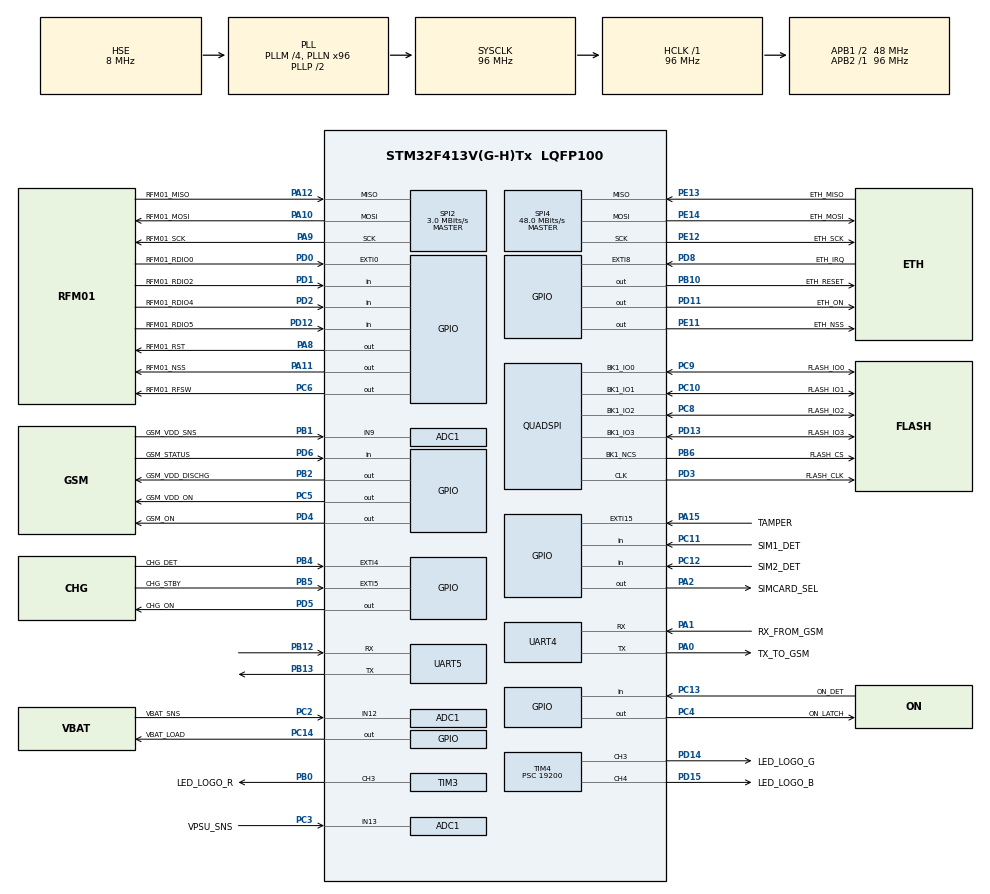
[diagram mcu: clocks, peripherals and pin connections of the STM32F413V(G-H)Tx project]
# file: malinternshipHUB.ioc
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ADC1.Channel-0\#ChannelRegularConversion=ADC_CHANNEL_12
ADC1.Channel-4\#ChannelRegularConversion=ADC_CHANNEL_13
ADC1.Channel-6\#ChannelRegularConversion=ADC_CHANNEL_9
ADC1.Channel-7\#ChannelRegularConversion=ADC_CHANNEL_VREFINT
ADC1.ClockPrescaler=ADC_CLOCK_SYNC_PCLK_DIV8
ADC1.ContinuousConvMode=ENABLE
ADC1.DMAContinuousRequests=ENABLE
ADC1.DiscontinuousConvMode=DISABLE
ADC1.EOCSelection=ADC_EOC_SEQ_CONV
ADC1.ExternalTrigConv=ADC_SOFTWARE_START
ADC1.InjNumberOfConversion=0
ADC1.NbrOfConversion=4
ADC1.NbrOfConversionFlag=1
ADC1.Rank-0\#ChannelRegularConversion=1
ADC1.Rank-4\#ChannelRegularConversion=2
ADC1.Rank-6\#ChannelRegularConversion=3
ADC1.Rank-7\#ChannelRegularConversion=4
ADC1.SamplingTime-0\#ChannelRegularConversion=ADC_SAMPLETIME_84CYCLES
ADC1.SamplingTime-4\#ChannelRegularConversion=ADC_SAMPLETIME_84CYCLES
ADC1.SamplingTime-6\#ChannelRegularConversion=ADC_SAMPLETIME_84CYCLES
ADC1.SamplingTime-7\#ChannelRegularConversion=ADC_SAMPLETIME_84CYCLES
ADC1.ScanConvMode=ENABLE
ADC1.master=1
Dma.ADC1.7.Direction=DMA_PERIPH_TO_MEMORY
Dma.ADC1.7.FIFOMode=DMA_FIFOMODE_DISABLE
Dma.ADC1.7.Instance=DMA2_Stream4
Dma.ADC1.7.MemDataAlignment=DMA_MDATAALIGN_WORD
Dma.ADC1.7.MemInc=DMA_MINC_ENABLE
Dma.ADC1.7.Mode=DMA_CIRCULAR
Dma.ADC1.7.PeriphDataAlignment=DMA_PDATAALIGN_WORD
Dma.ADC1.7.PeriphInc=DMA_PINC_DISABLE
Dma.ADC1.7.Priority=DMA_PRIORITY_HIGH
Dma.QUADSPI.8.Direction=DMA_PERIPH_TO_MEMORY
Dma.QUADSPI.8.FIFOMode=DMA_FIFOMODE_DISABLE
Dma.QUADSPI.8.Instance=DMA2_Stream7
Dma.QUADSPI.8.MemDataAlignment=DMA_MDATAALIGN_BYTE
Dma.QUADSPI.8.MemInc=DMA_MINC_ENABLE
Dma.QUADSPI.8.Mode=DMA_NORMAL
Dma.QUADSPI.8.PeriphDataAlignment=DMA_PDATAALIGN_BYTE
Dma.QUADSPI.8.PeriphInc=DMA_PINC_DISABLE
Dma.QUADSPI.8.Priority=DMA_PRIORITY_MEDIUM
Dma.Request0=UART5_RX
Dma.Request1=UART5_TX
Dma.Request2=SPI2_RX
Dma.Request3=SPI2_TX
Dma.Request4=SPI4_RX
Dma.Request5=SPI4_TX
Dma.Request6=UART4_RX
Dma.Request7=ADC1
Dma.Request8=QUADSPI
Dma.SPI2_RX.2.Direction=DMA_PERIPH_TO_MEMORY
Dma.SPI2_RX.2.FIFOMode=DMA_FIFOMODE_DISABLE
Dma.SPI2_RX.2.Instance=DMA1_Stream3
Dma.SPI2_RX.2.MemDataAlignment=DMA_MDATAALIGN_BYTE
Dma.SPI2_RX.2.MemInc=DMA_MINC_ENABLE
Dma.SPI2_RX.2.Mode=DMA_NORMAL
Dma.SPI2_RX.2.PeriphDataAlignment=DMA_PDATAALIGN_BYTE
Dma.SPI2_RX.2.PeriphInc=DMA_PINC_DISABLE
Dma.SPI2_RX.2.Priority=DMA_PRIORITY_HIGH
Dma.SPI2_TX.3.Direction=DMA_MEMORY_TO_PERIPH
Dma.SPI2_TX.3.FIFOMode=DMA_FIFOMODE_DISABLE
Dma.SPI2_TX.3.Instance=DMA1_Stream4
Dma.SPI2_TX.3.MemDataAlignment=DMA_MDATAALIGN_BYTE
Dma.SPI2_TX.3.MemInc=DMA_MINC_ENABLE
Dma.SPI2_TX.3.Mode=DMA_NORMAL
Dma.SPI2_TX.3.PeriphDataAlignment=DMA_PDATAALIGN_BYTE
Dma.SPI2_TX.3.PeriphInc=DMA_PINC_DISABLE
Dma.SPI2_TX.3.Priority=DMA_PRIORITY_MEDIUM
Dma.SPI4_RX.4.Direction=DMA_PERIPH_TO_MEMORY
Dma.SPI4_RX.4.FIFOMode=DMA_FIFOMODE_DISABLE
Dma.SPI4_RX.4.Instance=DMA2_Stream0
Dma.SPI4_RX.4.MemDataAlignment=DMA_MDATAALIGN_BYTE
Dma.SPI4_RX.4.MemInc=DMA_MINC_ENABLE
Dma.SPI4_RX.4.Mode=DMA_NORMAL
Dma.SPI4_RX.4.PeriphDataAlignment=DMA_PDATAALIGN_BYTE
Dma.SPI4_RX.4.PeriphInc=DMA_PINC_DISABLE
Dma.SPI4_RX.4.Priority=DMA_PRIORITY_HIGH
Dma.SPI4_TX.5.Direction=DMA_MEMORY_TO_PERIPH
Dma.SPI4_TX.5.FIFOMode=DMA_FIFOMODE_DISABLE
Dma.SPI4_TX.5.Instance=DMA2_Stream1
Dma.SPI4_TX.5.MemDataAlignment=DMA_MDATAALIGN_BYTE
Dma.SPI4_TX.5.MemInc=DMA_MINC_ENABLE
Dma.SPI4_TX.5.Mode=DMA_NORMAL
Dma.SPI4_TX.5.PeriphDataAlignment=DMA_PDATAALIGN_BYTE
Dma.SPI4_TX.5.PeriphInc=DMA_PINC_DISABLE
Dma.SPI4_TX.5.Priority=DMA_PRIORITY_MEDIUM
Dma.UART4_RX.6.Direction=DMA_PERIPH_TO_MEMORY
Dma.UART4_RX.6.FIFOMode=DMA_FIFOMODE_DISABLE
Dma.UART4_RX.6.Instance=DMA1_Stream2
Dma.UART4_RX.6.MemDataAlignment=DMA_MDATAALIGN_BYTE
Dma.UART4_RX.6.MemInc=DMA_MINC_ENABLE
Dma.UART4_RX.6.Mode=DMA_CIRCULAR
Dma.UART4_RX.6.PeriphDataAlignment=DMA_PDATAALIGN_BYTE
Dma.UART4_RX.6.PeriphInc=DMA_PINC_DISABLE
Dma.UART4_RX.6.Priority=DMA_PRIORITY_LOW
Dma.UART5_RX.0.Direction=DMA_PERIPH_TO_MEMORY
Dma.UART5_RX.0.FIFOMode=DMA_FIFOMODE_DISABLE
Dma.UART5_RX.0.Instance=DMA1_Stream0
Dma.UART5_RX.0.MemDataAlignment=DMA_MDATAALIGN_BYTE
Dma.UART5_RX.0.MemInc=DMA_MINC_ENABLE
Dma.UART5_RX.0.Mode=DMA_NORMAL
Dma.UART5_RX.0.PeriphDataAlignment=DMA_PDATAALIGN_BYTE
Dma.UART5_RX.0.PeriphInc=DMA_PINC_DISABLE
Dma.UART5_RX.0.Priority=DMA_PRIORITY_MEDIUM
Dma.UART5_TX.1.Direction=DMA_MEMORY_TO_PERIPH
Dma.UART5_TX.1.FIFOMode=DMA_FIFOMODE_DISABLE
Dma.UART5_TX.1.Instance=DMA1_Stream7
Dma.UART5_TX.1.MemDataAlignment=DMA_MDATAALIGN_BYTE
Dma.UART5_TX.1.MemInc=DMA_MINC_ENABLE
Dma.UART5_TX.1.Mode=DMA_NORMAL
Dma.UART5_TX.1.PeriphDataAlignment=DMA_PDATAALIGN_BYTE
Dma.UART5_TX.1.PeriphInc=DMA_PINC_DISABLE
Dma.UART5_TX.1.Priority=DMA_PRIORITY_MEDIUM
Mcu.Family=STM32F4
Mcu.Name=STM32F413V(G-H)Tx
Mcu.Package=LQFP100
Mcu.UserConstants=LOG_UART,huart5;MODEM_UART,huart4;ETH_SPI,hspi4;RFM_SPI,hspi2;FLASH_QSPI,hqspi;LED_R_TIM,htim3;LED_R_CH,TIM_CHANNEL_3;LED_G_TIM,htim4;LED_G_CH,TIM_CHANNEL_3;LED_B_TIM,htim4;LED_B_CH,TIM_CHANNEL_4
NVIC.ADC_IRQn=true\:0\:0\:false\:false\:true\:false\:true\:true\:true
NVIC.DMA1_Stream0_IRQn=true\:0\:0\:false\:false\:true\:false\:false\:true\:true
NVIC.DMA1_Stream2_IRQn=true\:0\:0\:false\:false\:true\:false\:false\:true\:true
NVIC.DMA1_Stream3_IRQn=true\:0\:0\:false\:false\:true\:false\:false\:true\:true
NVIC.DMA1_Stream4_IRQn=true\:0\:0\:false\:false\:true\:false\:false\:true\:true
NVIC.DMA1_Stream7_IRQn=true\:0\:0\:false\:false\:true\:false\:false\:true\:true
NVIC.DMA2_Stream0_IRQn=true\:0\:0\:false\:false\:true\:false\:false\:true\:true
NVIC.DMA2_Stream1_IRQn=true\:0\:0\:false\:false\:true\:false\:false\:true\:true
NVIC.DMA2_Stream4_IRQn=true\:0\:0\:false\:false\:true\:false\:false\:true\:true
NVIC.DMA2_Stream7_IRQn=true\:0\:0\:false\:false\:true\:false\:false\:true\:true
NVIC.EXTI0_IRQn=true\:0\:0\:false\:false\:true\:false\:true\:true\:true
NVIC.EXTI15_10_IRQn=true\:0\:0\:false\:false\:true\:false\:true\:true\:true
NVIC.EXTI4_IRQn=true\:0\:0\:false\:false\:true\:false\:true\:true\:true
NVIC.EXTI9_5_IRQn=true\:0\:0\:false\:false\:true\:false\:true\:true\:true
NVIC.PriorityGroup=NVIC_PRIORITYGROUP_4
NVIC.QUADSPI_IRQn=true\:0\:0\:false\:false\:true\:false\:true\:true\:true
NVIC.SPI2_IRQn=true\:0\:0\:false\:false\:true\:false\:true\:true\:true
NVIC.SPI4_IRQn=true\:0\:0\:false\:false\:true\:false\:true\:true\:true
NVIC.TIM7_IRQn=true\:0\:0\:false\:false\:true\:false\:true\:true\:true
NVIC.TIM8_UP_TIM13_IRQn=true\:15\:0\:false\:false\:true\:false\:false\:true\:true
NVIC.TimeBase=TIM8_UP_TIM13_IRQn
NVIC.TimeBaseIP=TIM13
NVIC.UART4_IRQn=true\:0\:0\:false\:false\:true\:false\:true\:true\:true
NVIC.UART5_IRQn=true\:0\:0\:false\:false\:true\:false\:true\:true\:true
PA0.GPIO_Label=TX_TO_GSM
PA0.Mode=Asynchronous
PA0.Signal=UART4_TX
PA1.GPIO_Label=RX_FROM_GSM
PA1.Mode=Asynchronous
PA1.Signal=UART4_RX
PA10.GPIO_Label=RFM01_MOSI
PA10.Mode=Full_Duplex_Master
PA10.Signal=SPI2_MOSI
PA11.GPIO_Label=RFM01_NSS
PA11.PinState=GPIO_PIN_SET
PA11.Signal=GPIO_Output
PA12.GPIO_Label=RFM01_MISO
PA12.Mode=Full_Duplex_Master
PA12.Signal=SPI2_MISO
PA13.Mode=Serial_Wire
PA13.Signal=SYS_JTMS-SWDIO
PA14.Mode=Serial_Wire
PA14.Signal=SYS_JTCK-SWCLK
PA15.GPIO_Label=TAMPER
PA15.GPIO_ModeDefaultEXTI=GPIO_MODE_IT_RISING_FALLING
PA15.GPIO_PuPd=GPIO_PULLUP
PA15.Signal=GPXTI15
PA2.GPIO_Label=SIMCARD_SEL
PA2.Signal=GPIO_Output
PA8.GPIO_Label=RFM01_RST
PA8.Signal=GPIO_Output
PA9.GPIO_Label=RFM01_SCK
PA9.Mode=Full_Duplex_Master
PA9.Signal=SPI2_SCK
PB0.GPIO_Label=LED_LOGO_R
PB0.Signal=S_TIM3_CH3
PB1.GPIO_Label=GSM_VDD_SNS
PB1.Signal=ADCx_IN9
PB10.GPIO_Label=ETH_RESET
PB10.PinState=GPIO_PIN_SET
PB10.Signal=GPIO_Output
PB12.Mode=Asynchronous
PB12.Signal=UART5_RX
PB13.Mode=Asynchronous
PB13.Signal=UART5_TX
PB2.GPIO_Label=GSM_VDD_DISCHG
PB2.Signal=GPIO_Output
PB4.GPIO_Label=CHG_DET
PB4.GPIO_ModeDefaultEXTI=GPIO_MODE_IT_RISING_FALLING
PB4.Signal=GPXTI4
PB5.GPIO_Label=CHG_STBY
PB5.GPIO_ModeDefaultEXTI=GPIO_MODE_IT_RISING_FALLING
PB5.Signal=GPXTI5
PB6.GPIO_Label=FLASH_CS
PB6.Mode=Single Bank 1
PB6.Signal=QUADSPI_BK1_NCS
PC10.GPIO_Label=FLASH_IO1
PC10.Mode=Single Bank 1
PC10.Signal=QUADSPI_BK1_IO1
PC11.GPIO_Label=SIM1_DET
PC11.GPIO_PuPd=GPIO_PULLUP
PC11.Signal=GPIO_Input
PC12.GPIO_Label=SIM2_DET
PC12.GPIO_PuPd=GPIO_PULLUP
PC12.Signal=GPIO_Input
PC13.GPIO_Label=ON_DET
PC13.Signal=GPIO_Input
PC14-OSC32_IN.GPIO_Label=VBAT_LOAD
PC14-OSC32_IN.Signal=GPIO_Output
PC2.GPIO_Label=VBAT_SNS
PC2.Signal=ADCx_IN12
PC3.GPIO_Label=VPSU_SNS
PC3.Signal=ADCx_IN13
PC4.GPIO_Label=ON_LATCH
PC4.Signal=GPIO_Output
PC5.GPIO_Label=GSM_VDD_ON
PC5.PinState=GPIO_PIN_RESET
PC5.Signal=GPIO_Output
PC6.GPIO_Label=RFM01_RFSW
PC6.Signal=GPIO_Output
PC8.GPIO_Label=FLASH_IO2
PC8.Mode=Single Bank 1
PC8.Signal=QUADSPI_BK1_IO2
PC9.GPIO_Label=FLASH_IO0
PC9.Mode=Single Bank 1
PC9.Signal=QUADSPI_BK1_IO0
PD0.GPIO_Label=RFM01_RDIO0
PD0.Signal=GPXTI0
PD1.GPIO_Label=RFM01_RDIO2
PD1.Signal=GPIO_Input
PD11.GPIO_Label=ETH_ON
PD11.Signal=GPIO_Output
PD12.GPIO_Label=RFM01_RDIO5
PD12.Signal=GPIO_Input
PD13.GPIO_Label=FLASH_IO3
PD13.Mode=Single Bank 1
PD13.Signal=QUADSPI_BK1_IO3
PD14.GPIO_Label=LED_LOGO_G
PD14.Signal=S_TIM4_CH3
PD15.GPIO_Label=LED_LOGO_B
PD15.Signal=S_TIM4_CH4
PD2.GPIO_Label=RFM01_RDIO4
PD2.Signal=GPIO_Input
PD3.GPIO_Label=FLASH_CLK
PD3.Mode=Single Bank 1
PD3.Signal=QUADSPI_CLK
PD4.GPIO_Label=GSM_ON
PD4.GPIO_ModeDefaultOutputPP=GPIO_MODE_OUTPUT_PP
PD4.GPIO_PuPd=GPIO_NOPULL
PD4.PinState=GPIO_PIN_SET
PD4.Signal=GPIO_Output
PD5.GPIO_Label=CHG_ON
PD5.PinState=GPIO_PIN_SET
PD5.Signal=GPIO_Output
PD6.GPIO_Label=GSM_STATUS
PD6.Signal=GPIO_Input
PD8.GPIO_Label=ETH_IRQ
PD8.GPIO_ModeDefaultEXTI=GPIO_MODE_IT_FALLING
PD8.Signal=GPXTI8
PE11.GPIO_Label=ETH_NSS
PE11.GPIO_Speed=GPIO_SPEED_FREQ_HIGH
PE11.PinState=GPIO_PIN_SET
PE11.Signal=GPIO_Output
PE12.GPIO_Label=ETH_SCK
PE12.Mode=Full_Duplex_Master
PE12.Signal=SPI4_SCK
PE13.GPIO_Label=ETH_MISO
PE13.Mode=Full_Duplex_Master
PE13.Signal=SPI4_MISO
PE14.GPIO_Label=ETH_MOSI
PE14.Mode=Full_Duplex_Master
PE14.Signal=SPI4_MOSI
PH0\ -\ OSC_IN.Mode=HSE-External-Oscillator
PH0\ -\ OSC_IN.Signal=RCC_OSC_IN
PH1\ -\ OSC_OUT.Mode=HSE-External-Oscillator
PH1\ -\ OSC_OUT.Signal=RCC_OSC_OUT
ProjectManager.HeapSize=0x200
ProjectManager.StackSize=0x400
ProjectManager.TargetToolchain=Makefile
QUADSPI.ClockMode=QSPI_CLOCK_MODE_0
QUADSPI.ClockPrescaler=1
QUADSPI.FifoThreshold=32
QUADSPI.FlashSize=24
RCC.AHBFreq_Value=96000000
RCC.APB1CLKDivider=RCC_HCLK_DIV2
RCC.APB1Freq_Value=48000000
RCC.APB1TimFreq_Value=96000000
RCC.APB2Freq_Value=96000000
RCC.APB2TimFreq_Value=96000000
RCC.CortexFreq_Value=96000000
RCC.HCLKFreq_Value=96000000
RCC.HSE_VALUE=8000000
RCC.PLLM=4
RCC.PLLN=96
RCC.PLLSourceVirtual=RCC_PLLSOURCE_HSE
RCC.SYSCLKFreq_VALUE=96000000
RCC.SYSCLKSource=RCC_SYSCLKSOURCE_PLLCLK
RCC.USBFreq_Value=96000000
RCC.VCOOutputFreq_Value=192000000
SH.ADCx_IN12.0=ADC1_IN12,IN12
SH.ADCx_IN13.0=ADC1_IN13,IN13
SH.ADCx_IN9.0=ADC1_IN9,IN9
SH.S_TIM3_CH3.0=TIM3_CH3,PWM Generation3 CH3
SH.S_TIM4_CH3.0=TIM4_CH3,PWM Generation3 CH3
SH.S_TIM4_CH4.0=TIM4_CH4,PWM Generation4 CH4
SPI2.BaudRatePrescaler=SPI_BAUDRATEPRESCALER_16
SPI2.CalculateBaudRate=3.0 MBits/s
SPI2.Direction=SPI_DIRECTION_2LINES
SPI2.Mode=SPI_MODE_MASTER
SPI2.VirtualType=VM_MASTER
SPI4.CLKPhase=SPI_PHASE_1EDGE
SPI4.CLKPolarity=SPI_POLARITY_LOW
SPI4.CalculateBaudRate=48.0 MBits/s
SPI4.Direction=SPI_DIRECTION_2LINES
SPI4.Mode=SPI_MODE_MASTER
SPI4.VirtualType=VM_MASTER
STMicroelectronics.X-CUBE-AZRTOS-F4.1.1.0.TX_APP_MEM_POOL_SIZE=61440
STMicroelectronics.X-CUBE-AZRTOS-F4.1.1.0.TX_MINIMUM_STACK=512
STMicroelectronics.X-CUBE-AZRTOS-F4.1.1.0.TX_TIMER_THREAD_PRIORITY=2
STMicroelectronics.X-CUBE-AZRTOS-F4.1.1.0.TX_TIMER_TICKS_PER_SECOND=1000
STMicroelectronics.X-CUBE-AZRTOS-F4.1.1.0.ThreadXCcRTOSJjThreadXJjCore=true
STMicroelectronics.X-CUBE-AZRTOS-F4.1.1.0_IsAnAzureRtosMw=true
TIM3.AutoReloadPreload=TIM_AUTORELOAD_PRELOAD_ENABLE
TIM3.Channel-PWM\ Generation3\ CH3=TIM_CHANNEL_3
TIM3.Period=100
TIM3.Prescaler=19200
TIM3.Pulse-PWM\ Generation3\ CH3=0
TIM4.AutoReloadPreload=TIM_AUTORELOAD_PRELOAD_ENABLE
TIM4.Channel-PWM\ Generation3\ CH3=TIM_CHANNEL_3
TIM4.Channel-PWM\ Generation4\ CH4=TIM_CHANNEL_4
TIM4.Period=100
TIM4.Prescaler=19200
TIM4.Pulse-PWM\ Generation3\ CH3=0
TIM4.Pulse-PWM\ Generation4\ CH4=0
TIM7.Period=64000-1
TIM7.Prescaler=60-1
UART4.VirtualMode=Asynchronous
UART5.VirtualMode=Asynchronous
VP_ADC1_Vref_Input.Mode=IN-Vrefint
VP_IWDG_VS_IWDG.Mode=IWDG_Activate
VP_STMicroelectronics.X-CUBE-AZRTOS-F4_VS_RTOSJjThreadX_6.1.10_1.1.0.Mode=RTOSJjThreadX
VP_SYS_VS_tim13.Mode=TIM13
VP_TIM3_VS_ClockSourceINT.Mode=Internal
VP_TIM4_VS_ClockSourceINT.Mode=Internal
VP_TIM7_VS_ClockSourceINT.Mode=Enable_Timer
board=custom

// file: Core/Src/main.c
/* USER CODE BEGIN Header */

/**
 ******************************************************************************
 * @file           : main.c
 * @brief          : Main program body
 ******************************************************************************
 * @attention
 *
 * Copyright (c) 2022 STMicroelectronics.
 * All rights reserved.
 *
 * This software is licensed under terms that can be found in the LICENSE file
 * in the root directory of this software component.
 * If no LICENSE file comes with this software, it is provided AS-IS.
 *
 ******************************************************************************
 */
/* USER CODE END Header */
#include "main.h"
#include "app_threadx.h"
#include "adc.h"
#include "dma.h"
#include "iwdg.h"
#include "quadspi.h"
#include "spi.h"
#include "tim.h"
#include "usart.h"
#include "gpio.h"

/* USER CODE BEGIN Includes */
#include "loglib.h"
#include "parser.h"
#include "boot_reason.h"
/* USER CODE END Includes */

/* USER CODE BEGIN PV */

void GOD_TIM_Callback(TIM_HandleTypeDef *htim);

/* USER CODE END PV */

void SystemClock_Config(void);

int main(void) {

    /* MCU Configuration--------------------------------------------------------*/

    /* Reset of all peripherals, Initializes the Flash interface and the Systick. */
    HAL_Init();

    /* Configure the system clock */
    SystemClock_Config();

    /* USER CODE BEGIN SysInit */
    GENERAL_GetResetStatus();
    /* USER CODE END SysInit */

    /* Initialize all configured peripherals */
    MX_GPIO_Init();
    MX_DMA_Init();
    MX_UART5_Init();
    MX_SPI2_Init();
    MX_SPI4_Init();
    MX_TIM3_Init();
    MX_TIM4_Init();
    MX_ADC1_Init();
    MX_QUADSPI_Init();
    MX_UART4_Init();
    MX_TIM7_Init();
    MX_IWDG_Init();

    MX_ThreadX_Init();

    /* We should never get here as control is now taken by the scheduler */
    /* Infinite loop */
    while (1) {

    }
}

void SystemClock_Config(void) {
    RCC_OscInitTypeDef RCC_OscInitStruct = { 0 };
    RCC_ClkInitTypeDef RCC_ClkInitStruct = { 0 };

    /** Configure the main internal regulator output voltage
     */
    __HAL_RCC_PWR_CLK_ENABLE();
    __HAL_PWR_VOLTAGESCALING_CONFIG(PWR_REGULATOR_VOLTAGE_SCALE1);

    /** Initializes the RCC Oscillators according to the specified parameters
     * in the RCC_OscInitTypeDef structure.
     */
    RCC_OscInitStruct.OscillatorType = RCC_OSCILLATORTYPE_LSI | RCC_OSCILLATORTYPE_HSE;
    RCC_OscInitStruct.HSEState = RCC_HSE_ON;
    RCC_OscInitStruct.LSIState = RCC_LSI_ON;
    RCC_OscInitStruct.PLL.PLLState = RCC_PLL_ON;
    RCC_OscInitStruct.PLL.PLLSource = RCC_PLLSOURCE_HSE;
    RCC_OscInitStruct.PLL.PLLM = 4;
    RCC_OscInitStruct.PLL.PLLN = 96;
    RCC_OscInitStruct.PLL.PLLP = RCC_PLLP_DIV2;
    RCC_OscInitStruct.PLL.PLLQ = 2;
    RCC_OscInitStruct.PLL.PLLR = 2;
    if (HAL_RCC_OscConfig(&RCC_OscInitStruct) != HAL_OK) {
        Error_Handler();
    }

    /** Initializes the CPU, AHB and APB buses clocks
     */
    RCC_ClkInitStruct.ClockType = RCC_CLOCKTYPE_HCLK | RCC_CLOCKTYPE_SYSCLK | RCC_CLOCKTYPE_PCLK1 | RCC_CLOCKTYPE_PCLK2;
    RCC_ClkInitStruct.SYSCLKSource = RCC_SYSCLKSOURCE_PLLCLK;
    RCC_ClkInitStruct.AHBCLKDivider = RCC_SYSCLK_DIV1;
    RCC_ClkInitStruct.APB1CLKDivider = RCC_HCLK_DIV2;
    RCC_ClkInitStruct.APB2CLKDivider = RCC_HCLK_DIV1;

    if (HAL_RCC_ClockConfig(&RCC_ClkInitStruct, FLASH_LATENCY_3) != HAL_OK) {
        Error_Handler();
    }
}

/* USER CODE BEGIN 4 */
void HAL_UART_TxCpltCallback(UART_HandleTypeDef *huart) {
    // if (huart == &huart4) {
    //     MOD_TxCpltCallback();
    // }
    if (huart == &huart5) {
        LOG_TxCpltCallback();
    }
}

void HAL_UART_RxCpltCallback(UART_HandleTypeDef *huart) {
    if (huart == &huart5) {
        PARSER_RxCpltCallback();
    }
}

/* USER CODE END 4 */

void HAL_TIM_PeriodElapsedCallback(TIM_HandleTypeDef *htim) {
    /* USER CODE BEGIN Callback 0 */
    GOD_TIM_Callback(htim);
    /* USER CODE END Callback 0 */
    if (htim->Instance == TIM13) {
        HAL_IncTick();
    }
}

void Error_Handler(void) {
    __disable_irq();
    while (1) {
    }
}
